AUTOSAR XML (schema 00048)
package /HuaweiMDC/FunctionalSoftware/Odometry/Execution
  executable odometry_execute
    root sw component prototype odometry_root_swc: application-type=odometry_base
package /HuaweiMDC/FunctionalSoftware/Odometry/SwComponent
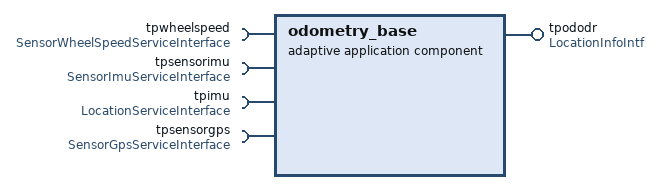
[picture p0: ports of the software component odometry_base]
  adaptive application sw component type odometry_base
    provide port tpododr: provided-interface=LocationInfoIntf
    4 x require port:
      tpwheelspeed: required-interface=SensorWheelSpeedServiceInterface
      tpsensorimu: required-interface=SensorImuServiceInterface
      tpimu: required-interface=LocationServiceInterface
      tpsensorgps: required-interface=SensorGpsServiceInterface
